# nrf9230_engb_isimcore register map
Vendor: Nordic Semiconductor; Series: nRF92; File version: 1
CPU: CM0 r0p1, little endian, MPU, no FPU, 2 interrupt priority bits, 32 interrupts
Registers are 32-bit, read-write, reset 0x0 unless marked. A register's access mark holds for its fields unless they carry their own. Offsets are from the block's base; [hi:lo] are bit positions; 'fields as' and 'values as' point back to an identical list.

## MHUIRQMAP_NS — MHU IRQ mapper 0
Base 0x47025000
Same registers: MHUIRQMAP_S 0x57025000
0x100 EVENTS_MHU0RCVIRQCOMB — Unspecified
  [0] EVENTS_MHU0RCVIRQCOMB
    0=NotGenerated (Event not generated); 1=Generated (Event generated)
0x104 EVENTS_MHU0RCVIRQ0 — Unspecified
  [0] EVENTS_MHU0RCVIRQ0
    values as EVENTS_MHU0RCVIRQCOMB.EVENTS_MHU0RCVIRQCOMB
0x108 EVENTS_MHU0RCVIRQ1 — Unspecified
  [0] EVENTS_MHU0RCVIRQ1
    values as EVENTS_MHU0RCVIRQCOMB.EVENTS_MHU0RCVIRQCOMB
0x10C EVENTS_MHU0SNDIRQACCESSNR2R — Unspecified
  [0] EVENTS_MHU0SNDIRQACCESSNR2R
    values as EVENTS_MHU0RCVIRQCOMB.EVENTS_MHU0RCVIRQCOMB
0x110 EVENTS_MHU0SNDIRQACCESSR2NR — Unspecified
  [0] EVENTS_MHU0SNDIRQACCESSR2NR
    values as EVENTS_MHU0RCVIRQCOMB.EVENTS_MHU0RCVIRQCOMB
0x114 EVENTS_MHU1RCVIRQCOMB — Unspecified
  [0] EVENTS_MHU1RCVIRQCOMB
    values as EVENTS_MHU0RCVIRQCOMB.EVENTS_MHU0RCVIRQCOMB
0x118 EVENTS_MHU1RCVIRQ0 — Unspecified
  [0] EVENTS_MHU1RCVIRQ0
    values as EVENTS_MHU0RCVIRQCOMB.EVENTS_MHU0RCVIRQCOMB
0x11C EVENTS_MHU1RCVIRQ1 — Unspecified
  [0] EVENTS_MHU1RCVIRQ1
    values as EVENTS_MHU0RCVIRQCOMB.EVENTS_MHU0RCVIRQCOMB
0x120 EVENTS_MHU1SNDIRQACCESSNR2R — Unspecified
  [0] EVENTS_MHU1SNDIRQACCESSNR2R
    values as EVENTS_MHU0RCVIRQCOMB.EVENTS_MHU0RCVIRQCOMB
0x124 EVENTS_MHU1SNDIRQACCESSR2NR — Unspecified
  [0] EVENTS_MHU1SNDIRQACCESSR2NR
    values as EVENTS_MHU0RCVIRQCOMB.EVENTS_MHU0RCVIRQCOMB
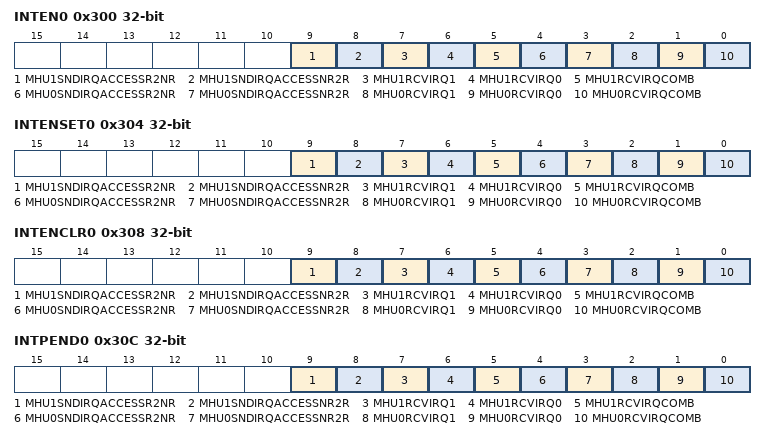
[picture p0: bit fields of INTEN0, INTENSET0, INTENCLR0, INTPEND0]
0x300 INTEN0 — Enable or disable interrupt
  [all] fields
    0=Disabled; 1=Enabled
  [9] MHU1SNDIRQACCESSR2NR — Enable or disable interrupt for event MHU1SNDIRQACCESSR2NR
  [8] MHU1SNDIRQACCESSNR2R — Enable or disable interrupt for event MHU1SNDIRQACCESSNR2R
  [7] MHU1RCVIRQ1 — Enable or disable interrupt for event MHU1RCVIRQ1
  [6] MHU1RCVIRQ0 — Enable or disable interrupt for event MHU1RCVIRQ0
  [5] MHU1RCVIRQCOMB — Enable or disable interrupt for event MHU1RCVIRQCOMB
  [4] MHU0SNDIRQACCESSR2NR — Enable or disable interrupt for event MHU0SNDIRQACCESSR2NR
  [3] MHU0SNDIRQACCESSNR2R — Enable or disable interrupt for event MHU0SNDIRQACCESSNR2R
  [2] MHU0RCVIRQ1 — Enable or disable interrupt for event MHU0RCVIRQ1
  [1] MHU0RCVIRQ0 — Enable or disable interrupt for event MHU0RCVIRQ0
  [0] MHU0RCVIRQCOMB — Enable or disable interrupt for event MHU0RCVIRQCOMB
0x304 INTENSET0 — Enable interrupt
  [all] fields
    on read: 0=Disabled (Read: Disabled); 1=Enabled (Read: Enabled) | on write: 1=Set (Enable)
  [9] MHU1SNDIRQACCESSR2NR — Write '1' to enable interrupt for event MHU1SNDIRQACCESSR2NR
  [8] MHU1SNDIRQACCESSNR2R — Write '1' to enable interrupt for event MHU1SNDIRQACCESSNR2R
  [7] MHU1RCVIRQ1 — Write '1' to enable interrupt for event MHU1RCVIRQ1
  [6] MHU1RCVIRQ0 — Write '1' to enable interrupt for event MHU1RCVIRQ0
  [5] MHU1RCVIRQCOMB — Write '1' to enable interrupt for event MHU1RCVIRQCOMB
  [4] MHU0SNDIRQACCESSR2NR — Write '1' to enable interrupt for event MHU0SNDIRQACCESSR2NR
  [3] MHU0SNDIRQACCESSNR2R — Write '1' to enable interrupt for event MHU0SNDIRQACCESSNR2R
  [2] MHU0RCVIRQ1 — Write '1' to enable interrupt for event MHU0RCVIRQ1
  [1] MHU0RCVIRQ0 — Write '1' to enable interrupt for event MHU0RCVIRQ0
  [0] MHU0RCVIRQCOMB — Write '1' to enable interrupt for event MHU0RCVIRQCOMB
0x308 INTENCLR0 — Disable interrupt
  [all] fields
    on read: 0=Disabled (Read: Disabled); 1=Enabled (Read: Enabled) | on write: 1=Clear (Disable)
  [9] MHU1SNDIRQACCESSR2NR — Write '1' to disable interrupt for event MHU1SNDIRQACCESSR2NR
  [8] MHU1SNDIRQACCESSNR2R — Write '1' to disable interrupt for event MHU1SNDIRQACCESSNR2R
  [7] MHU1RCVIRQ1 — Write '1' to disable interrupt for event MHU1RCVIRQ1
  [6] MHU1RCVIRQ0 — Write '1' to disable interrupt for event MHU1RCVIRQ0
  [5] MHU1RCVIRQCOMB — Write '1' to disable interrupt for event MHU1RCVIRQCOMB
  [4] MHU0SNDIRQACCESSR2NR — Write '1' to disable interrupt for event MHU0SNDIRQACCESSR2NR
  [3] MHU0SNDIRQACCESSNR2R — Write '1' to disable interrupt for event MHU0SNDIRQACCESSNR2R
  [2] MHU0RCVIRQ1 — Write '1' to disable interrupt for event MHU0RCVIRQ1
  [1] MHU0RCVIRQ0 — Write '1' to disable interrupt for event MHU0RCVIRQ0
  [0] MHU0RCVIRQCOMB — Write '1' to disable interrupt for event MHU0RCVIRQCOMB
0x30C INTPEND0 ro — Pending interrupts
  [all] fields
    on read: 0=NotPending (Read: Not pending); 1=Pending (Read: Pending)
  [9] MHU1SNDIRQACCESSR2NR — Read pending status of interrupt for event MHU1SNDIRQACCESSR2NR
  [8] MHU1SNDIRQACCESSNR2R — Read pending status of interrupt for event MHU1SNDIRQACCESSNR2R
  [7] MHU1RCVIRQ1 — Read pending status of interrupt for event MHU1RCVIRQ1
  [6] MHU1RCVIRQ0 — Read pending status of interrupt for event MHU1RCVIRQ0
  [5] MHU1RCVIRQCOMB — Read pending status of interrupt for event MHU1RCVIRQCOMB
  [4] MHU0SNDIRQACCESSR2NR — Read pending status of interrupt for event MHU0SNDIRQACCESSR2NR
  [3] MHU0SNDIRQACCESSNR2R — Read pending status of interrupt for event MHU0SNDIRQACCESSNR2R
  [2] MHU0RCVIRQ1 — Read pending status of interrupt for event MHU0RCVIRQ1
  [1] MHU0RCVIRQ0 — Read pending status of interrupt for event MHU0RCVIRQ0
  [0] MHU0RCVIRQCOMB — Read pending status of interrupt for event MHU0RCVIRQCOMB
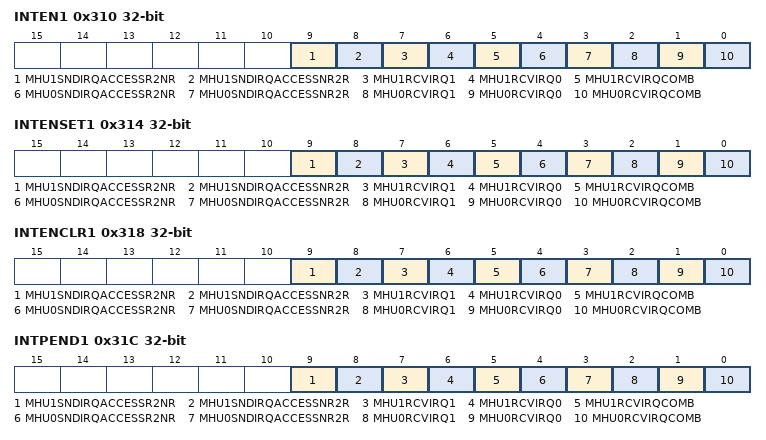
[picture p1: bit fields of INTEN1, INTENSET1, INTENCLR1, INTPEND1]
0x310 INTEN1 — Enable or disable interrupt
  fields as INTEN0
0x314 INTENSET1 — Enable interrupt
  fields as INTENSET0
0x318 INTENCLR1 — Disable interrupt
  fields as INTENCLR0
0x31C INTPEND1 ro — Pending interrupts
  fields as INTPEND0
